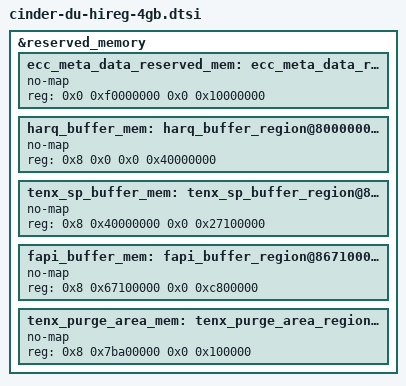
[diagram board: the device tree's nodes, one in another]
&reserved_memory {
	#address-cells = <2>;
	#size-cells = <2>;
	ranges;

	ecc_meta_data_reserved_mem: ecc_meta_data_reserved_region@f0000000 {
		no-map;
		reg = <0x0 0xf0000000 0x0 0x10000000>;
	};

	harq_buffer_mem: harq_buffer_region@800000000 {
		no-map;
		reg = <0x8 0x0 0x0 0x40000000>;
	};

	tenx_sp_buffer_mem: tenx_sp_buffer_region@840000000 {
		no-map;
		reg = <0x8 0x40000000 0x0 0x27100000>;
	};

	fapi_buffer_mem: fapi_buffer_region@867100000 {
		no-map;
		reg = <0x8 0x67100000 0x0 0xc800000>;
	};

	tenx_purge_area_mem: tenx_purge_area_region@87ba00000 {
		no-map;
		reg = <0x8 0x7ba00000 0x0 0x100000>;
	};

};
